# LPC11xxLV_LPC111x_LV register map
File version: 1
CPU: CM0 r0p0, little endian, no MPU, no FPU, 2 interrupt priority bits
Registers are 32-bit, read-write, reset 0x0 unless marked. A register's access mark holds for its fields unless they carry their own. Offsets are from the block's base; [hi:lo] are bit positions; 'fields as' and 'values as' point back to an identical list.

## IOCON — I/O configuration (IOCONFIG)
Base 0x40044000
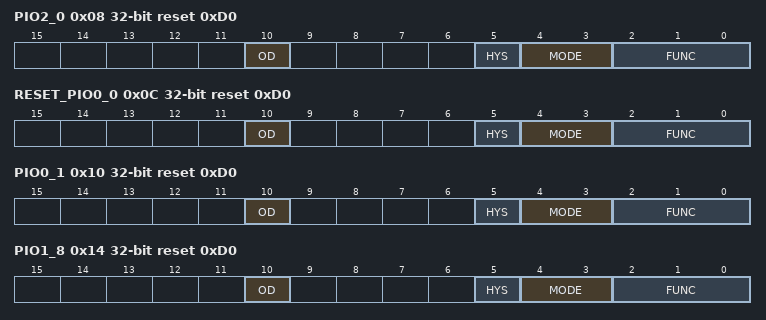
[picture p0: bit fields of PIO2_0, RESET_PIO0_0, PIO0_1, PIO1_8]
0x08 PIO2_0 reset 0xD0 — I/O configuration for pin PIO2_0/DTR/SSEL1
  [10] OD — Selects pseudo open-drain mode.
    0=STANDARD_GPIO_OUTPUT; 1=OPEN_DRAIN_OUTPUT
  [5] HYS — Hysteresis.
    0=DISABLE_; 1=ENABLE_
  [4:3] MODE — Selects function mode (on-chip pull-up/pull-down resistor control).
    0=INACTIVE_NO_PULL_DO (Inactive (no pull-down/pull-up resistor enabled).); 1=PULL_DOWN_RESISTOR_E (Pull-down resistor enabled.); 2=PULL_UP_RESISTOR_ENA (Pull-up resistor enabled.); 3=REPEATER_MODE_
  [2:0] FUNC — Selects pin function. All other values are reserved.
    0=SELECTS_FUNCTION_PIO (Selects function PIO2_0.); 1=SELECT_FUNCTION_DTR_
0x0C RESET_PIO0_0 reset 0xD0 — I/O configuration for pin RESET/PIO0_0
  [10] OD — Selects pseudo open-drain mode.
    0=STANDARD_GPIO_OUTPUT; 1=OPEN_DRAIN_OUTPUT
  [5] HYS — Hysteresis.
    0=DISABLE_; 1=ENABLE_
  [4:3] MODE — Selects function mode (on-chip pull-up/pull-down resistor control).
    values as PIO2_0.MODE
  [2:0] FUNC — Selects pin function. All other values are reserved.
    0=SELECTS_FUNCTION_RES (Selects function RESET.); 1=SELECTS_FUNCTION_PIO0_0
0x10 PIO0_1 reset 0xD0 — I/O configuration for pin PIO0_1/CLKOUT/CT32B0_MAT2
  [10] OD — Selects pseudo open-drain mode.
    0=STANDARD_GPIO_OUTPUT; 1=OPEN_DRAIN_OUTPUT
  [5] HYS — Hysteresis.
    0=DISABLE_; 1=ENABLE_
  [4:3] MODE — Selects function mode (on-chip pull-up/pull-down resistor control).
    values as PIO2_0.MODE
  [2:0] FUNC — Selects pin function. All other values are reserved.
    0=SELECTS_FUNCTION_PIO0_1; 1=SELECTS_FUNCTION_CLKOUT; 2=SELECTS_FUNCTION_CT32B0_MAT2
0x14 PIO1_8 reset 0xD0 — I/O configuration for pin PIO1_8/CT16B1_CAP0
  [10] OD — Selects pseudo open-drain mode.
    0=STANDARD_GPIO_OUTPUT; 1=OPEN_DRAIN_OUTPUT
  [5] HYS — Hysteresis.
    0=DISABLE_; 1=ENABLE_
  [4:3] MODE — Selects function mode (on-chip pull-up/pull-down resistor control).
    values as PIO2_0.MODE
  [2:0] FUNC — Selects pin function. All other values are reserved.
    0=SELECTS_FUNCTION_PIO1_8; 1=SELECTS_FUNCTION_CT16B1_CAP0
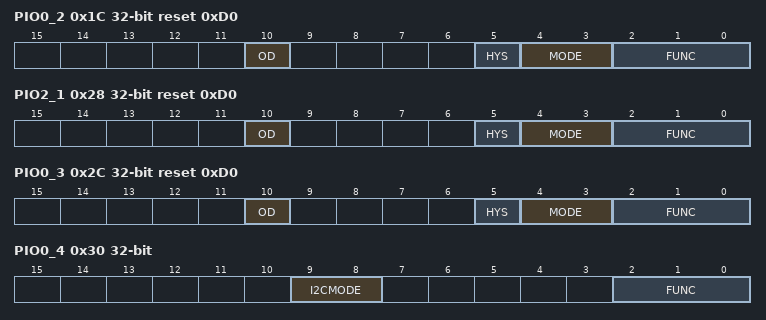
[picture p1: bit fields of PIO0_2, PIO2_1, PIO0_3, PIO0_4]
0x1C PIO0_2 reset 0xD0 — I/O configuration for pin PIO0_2/SSEL0/CT16B0_CAP0
  [10] OD — Selects pseudo open-drain mode.
    0=STANDARD_GPIO_OUTPUT; 1=OPEN_DRAIN_OUTPUT
  [5] HYS — Hysteresis.
    0=DISABLE_; 1=ENABLE_
  [4:3] MODE — Selects function mode (on-chip pull-up/pull-down resistor control).
    values as PIO2_0.MODE
  [2:0] FUNC — Selects pin function. All other values are reserved.
    0=SELECTS_FUNCTION_PIO0_2; 1=SELECTS_FUNCTION_SSE (Selects function SSEL0.); 2=SELECTS_FUNCTION_CT16B0_CAP0
0x28 PIO2_1 reset 0xD0 — I/O configuration for pin PIO2_1/DSR
  [10] OD — Selects pseudo open-drain mode.
    0=STANDARD_GPIO_OUTPUT; 1=OPEN_DRAIN_OUTPUT
  [5] HYS — Hysteresis.
    0=DISABLE_; 1=ENABLE_
  [4:3] MODE — Selects function mode (on-chip pull-up/pull-down resistor control).
    values as PIO2_0.MODE
  [2:0] FUNC — Selects pin function. All other values are reserved.
    0=SELECTS_FUNCTION_PIO2_1; 1=SELECT_FUNCTION_DSR_
0x2C PIO0_3 reset 0xD0 — I/O configuration for pin PIO0_3
  [10] OD — Selects pseudo open-drain mode.
    0=STANDARD_GPIO_OUTPUT; 1=OPEN_DRAIN_OUTPUT
  [5] HYS — Hysteresis.
    0=DISABLE_; 1=ENABLE_
  [4:3] MODE — Selects function mode (on-chip pull-up/pull-down resistor control).
    values as PIO2_0.MODE
  [2:0] FUNC — Selects pin function. All other values are reserved.
    0=SELECTS_FUNCTION_PIO0_3
0x30 PIO0_4 — I/O configuration for pin PIO0_4/SCL
  [9:8] I2CMODE — Selects I2C mode. Select Standard mode (I2CMODE = 00, default) or Standard I/O functionality (I2CMODE = 01) if the pin function is GPIO (FUNC = 000).
    0=STANDARD_MODE_FAST (Standard mode/ Fast-mode I2C.); 1=STANDARD_IO_FUNCTION (Standard I/O functionality); 2=FAST_MODE_PLUS_I2C
  [2:0] FUNC — Selects pin function. All other values are reserved.
    0=SELECTS_FUNCTION_PIO0_4 (Selects function PIO0_4 (open-drain pin).); 1=SELECTS_FUNCTION_SCL (Selects I2C function SCL (open-drain pin).)
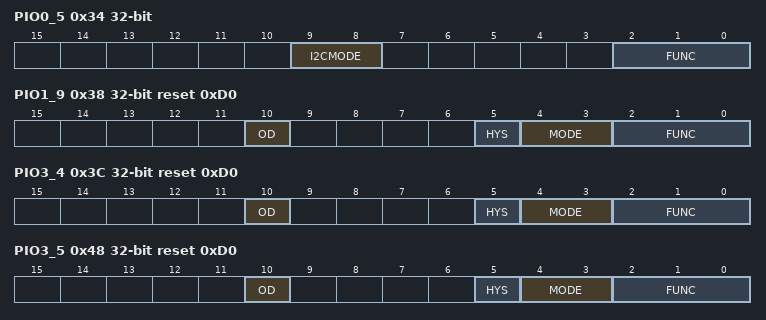
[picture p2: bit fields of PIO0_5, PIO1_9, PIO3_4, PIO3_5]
0x34 PIO0_5 — I/O configuration for pin PIO0_5/SDA
  [9:8] I2CMODE — Selects I2C mode. Select Standard mode (I2CMODE = 00, default) or Standard I/O functionality (I2CMODE = 01) if the pin function is GPIO (FUNC = 000).
    values as PIO0_4.I2CMODE
  [2:0] FUNC — Selects pin function. All other values are reserved.
    0=SELECTS_FUNCTION_PIO0_5 (Selects function PIO0_5 (open-drain pin).); 1=SELECTS_FUNCTION_SDA (Selects I2C function SDA (open-drain pin).)
0x38 PIO1_9 reset 0xD0 — I/O configuration for pin PIO1_9/CT16B1_MAT0/ MOSI1
  [10] OD — Selects pseudo open-drain mode.
    0=STANDARD_GPIO_OUTPUT; 1=OPEN_DRAIN_OUTPUT
  [5] HYS — Hysteresis.
    0=DISABLE_; 1=ENABLE_
  [4:3] MODE — Selects function mode (on-chip pull-up/pull-down resistor control).
    values as PIO2_0.MODE
  [2:0] FUNC — Selects pin function. All other values are reserved.
    0=SELECTS_FUNCTION_PIO1_9; 1=SELECTS_FUNCTION_CT16B1_MAT0
0x3C PIO3_4 reset 0xD0 — I/O configuration for pin PIO3_4/CT16B0_CAP1/RXD
  [10] OD — Selects pseudo open-drain mode.
    0=STANDARD_GPIO_OUTPUT; 1=OPEN_DRAIN_OUTPUT
  [5] HYS — Hysteresis.
    0=DISABLE_; 1=ENABLE_
  [4:3] MODE — Selects function mode (on-chip pull-up/pull-down resistor control).
    values as PIO2_0.MODE
  [2:0] FUNC — Selects pin function. All other values are reserved.
    0=SELECTS_FUNCTION_PIO3_4; 1=SELECTS_FUNCTION_CT16B0_CAP1; 2=SELECTS_FUNCTION_RXD (Selects function RXD. Also select the RXD location in the RXD_LOC register.)
0x48 PIO3_5 reset 0xD0 — I/O configuration for pin PIO3_5/CT16B1_CAP1/TXD
  [10] OD — Selects pseudo open-drain mode.
    0=STANDARD_GPIO_OUTPUT; 1=OPEN_DRAIN_OUTPUT
  [5] HYS — Hysteresis.
    0=DISABLE_; 1=ENABLE_
  [4:3] MODE — Selects function mode (on-chip pull-up/pull-down resistor control).
    values as PIO2_0.MODE
  [2:0] FUNC — Selects pin function. All other values are reserved.
    0=SELECTS_FUNCTION_PIO3_5; 1=SELECTS_FUNCTION_CT16B1_CAP1; 2=SELECTS_FUNCTION_TXD
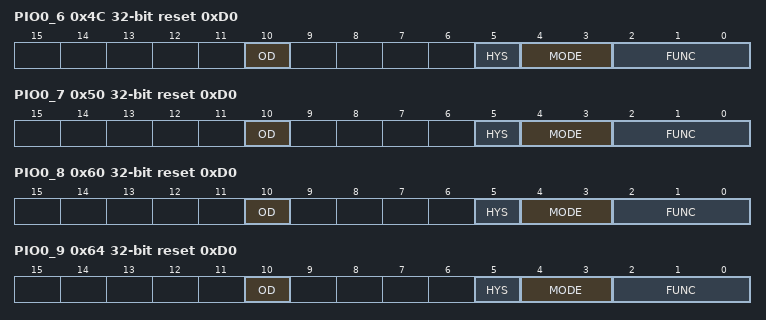
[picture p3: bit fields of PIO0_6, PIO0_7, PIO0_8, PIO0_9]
0x4C PIO0_6 reset 0xD0 — I/O configuration for pin PIO0_6/SCK0
  [10] OD — Selects pseudo open-drain mode.
    0=STANDARD_GPIO_OUTPUT; 1=OPEN_DRAIN_OUTPUT
  [5] HYS — Hysteresis.
    0=DISABLE_; 1=ENABLE_
  [4:3] MODE — Selects function mode (on-chip pull-up/pull-down resistor control).
    values as PIO2_0.MODE
  [2:0] FUNC — Selects pin function. All other values are reserved.
    0=SELECTS_FUNCTION_PIO0_6; 2=SELECTS_FUNCTION_SCK0 (Selects function SCK0 (only if pin PIO0_6/SCK0 selected in Table 147).)
0x50 PIO0_7 reset 0xD0 — I/O configuration for pin PIO0_7/CTS
  [10] OD — Selects pseudo open-drain mode.
    0=STANDARD_GPIO_OUTPUT; 1=OPEN_DRAIN_OUTPUT
  [5] HYS — Hysteresis.
    0=DISABLE_; 1=ENABLE_
  [4:3] MODE — Selects function mode (on-chip pull-up/pull-down resistor control).
    values as PIO2_0.MODE
  [2:0] FUNC — Selects pin function. All other values are reserved.
    0=SELECTS_FUNCTION_PIO (Selects function PIO0_7.); 1=SELECT_FUNCTION_CTS_
0x60 PIO0_8 reset 0xD0 — I/O configuration for pin PIO0_8/MISO0/CT16B0_MAT0
  [10] OD — Selects pseudo open-drain mode.
    0=STANDARD_GPIO_OUTPUT; 1=OPEN_DRAIN_OUTPUT
  [5] HYS — Hysteresis.
    0=DISABLE_; 1=ENABLE_
  [4:3] MODE — Selects function mode (on-chip pull-up/pull-down resistor control).
    values as PIO2_0.MODE
  [2:0] FUNC — Selects pin function. All other values are reserved.
    0=SELECTS_FUNCTION_PIO0_8; 1=SELECTS_FUNCTION_MISO0; 2=SELECTS_FUNCTION_CT16B0_MAT0
0x64 PIO0_9 reset 0xD0 — I/O configuration for pin PIO0_9/MOSI0/CT16B0_MAT1
  [10] OD — Selects pseudo open-drain mode.
    0=STANDARD_GPIO_OUTPUT; 1=OPEN_DRAIN_OUTPUT
  [5] HYS — Hysteresis.
    0=DISABLE_; 1=ENABLE_
  [4:3] MODE — Selects function mode (on-chip pull-up/pull-down resistor control).
    values as PIO2_0.MODE
  [2:0] FUNC — Selects pin function. All other values are reserved.
    0=SELECTS_FUNCTION_PIO0_9; 1=SELECTS_FUNCTION_MOSI0; 2=SELECTS_FUNCTION_CT16B0_MAT1
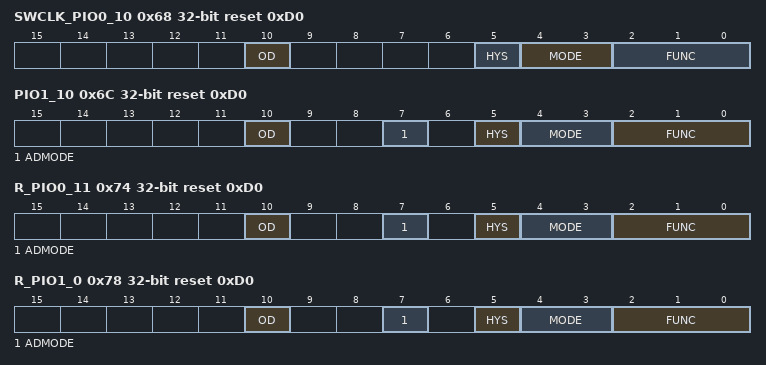
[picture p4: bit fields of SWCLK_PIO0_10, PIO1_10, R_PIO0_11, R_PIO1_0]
0x68 SWCLK_PIO0_10 reset 0xD0 — I/O configuration for pin SWCLK/PIO0_10/ SCK0/CT16B0_MAT2
  [10] OD — Selects pseudo open-drain mode.
    0=STANDARD_GPIO_OUTPUT; 1=OPEN_DRAIN_OUTPUT
  [5] HYS — Hysteresis.
    0=DISABLE_; 1=ENABLE_
  [4:3] MODE — Selects function mode (on-chip pull-up/pull-down resistor control).
    values as PIO2_0.MODE
  [2:0] FUNC — Selects pin function. All other values are reserved.
    0=SELECTS_FUNCTION_SWCLK; 1=SELECTS_FUNCTION_PIO0_10; 2=SELECTS_FUNCTION_SCK0 (Selects function SCK0 (only if pin SWCLK/PIO0_10/SCK0/CT16B0_MAT2 selected in Table 147).); 3=SELECTS_FUNCTION_CT16B0_MAT2
0x6C PIO1_10 reset 0xD0 — I/O configuration for pin PIO1_10/AD6/CT16B1_MAT1/ MISO1
  [10] OD — Selects pseudo open-drain mode.
    0=STANDARD_GPIO_OUTPUT; 1=OPEN_DRAIN_OUTPUT
  [7] ADMODE — Selects Analog/Digital mode
    0=ANALOG_INPUT_MODE; 1=DIGITAL_FUNCTIONAL_M (Digital functional mode)
  [5] HYS — Hysteresis.
    0=DISABLE_; 1=ENABLE_
  [4:3] MODE — Selects function mode (on-chip pull-up/pull-down resistor control).
    values as PIO2_0.MODE
  [2:0] FUNC — Selects pin function. All other values are reserved.
    0=SELECTS_FUNCTION_PIO1_10; 1=SELECTS_FUNCTION_AD6; 2=SELECTS_FUNCTION_CT16B1_MAT1
0x74 R_PIO0_11 reset 0xD0 — I/O configuration for pin R/PIO0_11/AD0/CT32B0_MAT3
  [10] OD — Selects pseudo open-drain mode.
    0=STANDARD_GPIO_OUTPUT; 1=OPEN_DRAIN_OUTPUT
  [7] ADMODE — Selects Analog/Digital mode
    values as PIO1_10.ADMODE
  [5] HYS — Hysteresis.
    0=DISABLE_; 1=ENABLE_
  [4:3] MODE — Selects function mode (on-chip pull-up/pull-down resistor control).
    values as PIO2_0.MODE
  [2:0] FUNC — Selects pin function. All other values are reserved.
    0=SELECTS_FUNCTION_R_ (Selects function R. This function is reserved. Select one of the alternate functions below.); 1=SELECTS_FUNCTION_PIO0_11; 2=SELECTS_FUNCTION_AD0; 3=SELECTS_FUNCTION_CT32B0_MAT3
0x78 R_PIO1_0 reset 0xD0 — I/O configuration for pin R/PIO1_0/AD1/CT32B1_CAP0
  [10] OD — Selects pseudo open-drain mode.
    0=STANDARD_GPIO_OUTPUT; 1=OPEN_DRAIN_OUTPUT
  [7] ADMODE — Selects Analog/Digital mode
    values as PIO1_10.ADMODE
  [5] HYS — Hysteresis.
    0=DISABLE_; 1=ENABLE_
  [4:3] MODE — Selects function mode (on-chip pull-up/pull-down resistor control).
    values as PIO2_0.MODE
  [2:0] FUNC — Selects pin function. All other values are reserved.
    0=SELECTS_FUNCTION_R_ (Selects function R. This function is reserved. Select one of the alternate functions below.); 1=SELECTS_FUNCTION_PIO1_0; 2=SELECTS_FUNCTION_AD1; 3=SELECTS_FUNCTION_CT32B1_CAP0
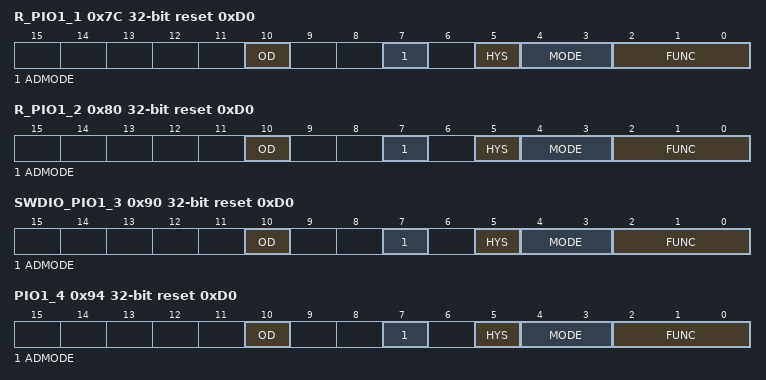
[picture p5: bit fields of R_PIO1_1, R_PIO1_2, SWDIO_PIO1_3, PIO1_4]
0x7C R_PIO1_1 reset 0xD0 — I/O configuration for pin R/PIO1_1/AD2/CT32B1_MAT0
  [10] OD — Selects pseudo open-drain mode.
    0=STANDARD_GPIO_OUTPUT; 1=OPEN_DRAIN_OUTPUT
  [7] ADMODE — Selects Analog/Digital mode
    values as PIO1_10.ADMODE
  [5] HYS — Hysteresis.
    0=DISABLE_; 1=ENABLE_
  [4:3] MODE — Selects function mode (on-chip pull-up/pull-down resistor control).
    values as PIO2_0.MODE
  [2:0] FUNC — Selects pin function. All other values are reserved.
    0=SELECTS_FUNCTION_R_ (Selects function R. This function is reserved. Select one of the alternate functions below.); 1=SELECTS_FUNCTION_PIO (Selects function PIO1_1.); 2=SELECTS_FUNCTION_AD2; 3=SELECTS_FUNCTION_CT3 (Selects function CT32B1_MAT0.)
0x80 R_PIO1_2 reset 0xD0 — I/O configuration for pin R/PIO1_2/AD3/CT32B1_MAT1
  [10] OD — Selects pseudo open-drain mode.
    0=STANDARD_GPIO_OUTPUT; 1=OPEN_DRAIN_OUTPUT
  [7] ADMODE — Selects Analog/Digital mode
    values as PIO1_10.ADMODE
  [5] HYS — Hysteresis.
    0=DISABLE_; 1=ENABLE_
  [4:3] MODE — Selects function mode (on-chip pull-up/pull-down resistor control).
    values as PIO2_0.MODE
  [2:0] FUNC — Selects pin function. All other values are reserved.
    0=SELECTS_FUNCTION_R_ (Selects function R. This function is reserved. Select one of the alternate functions below.); 1=SELECTS_FUNCTION_PIO1_2; 2=SELECTS_FUNCTION_AD3; 3=SELECTS_FUNCTION_CT32B1_MAT1
0x90 SWDIO_PIO1_3 reset 0xD0 — I/O configuration for pin SWDIO/PIO1_3/AD4/CT32B1_MAT2
  [10] OD — Selects pseudo open-drain mode.
    0=STANDARD_GPIO_OUTPUT; 1=OPEN_DRAIN_OUTPUT
  [7] ADMODE — Selects Analog/Digital mode
    values as PIO1_10.ADMODE
  [5] HYS — Hysteresis.
    0=DISABLE_; 1=ENABLE_
  [4:3] MODE — Selects function mode (on-chip pull-up/pull-down resistor control).
    values as PIO2_0.MODE
  [2:0] FUNC — Selects pin function. All other values are reserved.
    0=SELECTS_FUNCTION_SWDIO; 1=SELECTS_FUNCTION_PIO1_3; 2=SELECTS_FUNCTION_AD4; 3=SELECTS_FUNCTION_CT3 (Selects function CT32B1_MAT2.)
0x94 PIO1_4 reset 0xD0 — I/O configuration for pin PIO1_4/AD5/CT32B1_MAT3
  [10] OD — Selects pseudo open-drain mode.
    0=STANDARD_GPIO_OUTPUT; 1=OPEN_DRAIN_OUTPUT
  [7] ADMODE — Selects Analog/Digital mode
    values as PIO1_10.ADMODE
  [5] HYS — Hysteresis.
    0=DISABLE_; 1=ENABLE_
  [4:3] MODE — Selects function mode (on-chip pull-up/pull-down resistor control).
    values as PIO2_0.MODE
  [2:0] FUNC — Selects pin function. This pin functions as WAKEUP pin if the LPC111x/LPC11Cxx is in Deep power-down mode regardless of the value of FUNC. All other values are reserved.
    0=SELECTS_FUNCTION_PIO1_4; 1=SELECTS_FUNCTION_AD5; 2=SELECTS_FUNCTION_CT32B1_MAT3
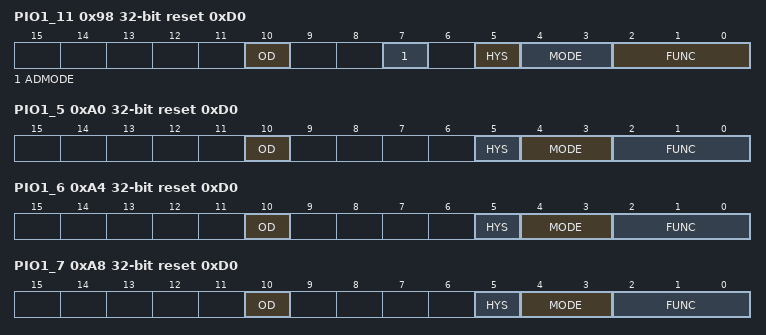
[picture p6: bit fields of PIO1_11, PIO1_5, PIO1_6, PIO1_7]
0x98 PIO1_11 reset 0xD0 — I/O configuration for pin PIO1_11/AD7/CT32B1_CAP1
  [10] OD — Selects pseudo open-drain mode.
    0=STANDARD_GPIO_OUTPUT; 1=OPEN_DRAIN_OUTPUT
  [7] ADMODE — Selects Analog/Digital mode
    values as PIO1_10.ADMODE
  [5] HYS — Hysteresis.
    0=DISABLE_; 1=ENABLE_
  [4:3] MODE — Selects function mode (on-chip pull-up/pull-down resistor control).
    values as PIO2_0.MODE
  [2:0] FUNC — Selects pin function. All other values are reserved.
    0=SELECTS_FUNCTION_PIO1_11; 1=SELECTS_FUNCTION_AD7; 2=SELECTS_FUNCTION_CT32B1_CAP1
0xA0 PIO1_5 reset 0xD0 — I/O configuration for pin PIO1_5/RTS/CT32B0_CAP0
  [10] OD — Selects pseudo open-drain mode.
    0=STANDARD_GPIO_OUTPUT; 1=OPEN_DRAIN_OUTPUT
  [5] HYS — Hysteresis.
    0=DISABLE_; 1=ENABLE_
  [4:3] MODE — Selects function mode (on-chip pull-up/pull-down resistor control).
    values as PIO2_0.MODE
  [2:0] FUNC — Selects pin function. All other values are reserved.
    0=SELECTS_FUNCTION_PIO1_5; 1=SELECTS_FUNCTION_RTS; 2=SELECTS_FUNCTION_CT32B0_CAP0
0xA4 PIO1_6 reset 0xD0 — I/O configuration for pin PIO1_6/RXD/CT32B0_MAT0
  [10] OD — Selects pseudo open-drain mode.
    0=STANDARD_GPIO_OUTPUT; 1=OPEN_DRAIN_OUTPUT
  [5] HYS — Hysteresis.
    0=DISABLE_; 1=ENABLE_
  [4:3] MODE — Selects function mode (on-chip pull-up/pull-down resistor control).
    values as PIO2_0.MODE
  [2:0] FUNC — Selects pin function. All other values are reserved.
    0=SELECTS_FUNCTION_PIO1_6; 1=SELECTS_FUNCTION_RXD (Selects function RXD. Also select the RXD location in the RXD_LOC register.); 2=SELECTS_FUNCTION_CT32B0_MAT0
0xA8 PIO1_7 reset 0xD0 — I/O configuration for pin PIO1_7/TXD/CT32B0_MAT1
  [10] OD — Selects pseudo open-drain mode.
    0=STANDARD_GPIO_OUTPUT; 1=OPEN_DRAIN_OUTPUT
  [5] HYS — Hysteresis.
    0=DISABLE_; 1=ENABLE_
  [4:3] MODE — Selects function mode (on-chip pull-up/pull-down resistor control).
    values as PIO2_0.MODE
  [2:0] FUNC — Selects pin function. All other values are reserved.
    0=SELECTS_FUNCTION_PIO1_7; 1=SELECTS_FUNCTION_TXD; 2=SELECTS_FUNCTION_CT32B0_MAT1
0xB0 SCK0_LOC — SCK0 pin location select register
  [1:0] SCKLOC — Selects pin location for SCK0 function.
    0=SELECTS_SCK0_FUNCTIO (Selects SCK0 function in pin location SWCLK/PIO0_10/SCK0/CT16B0_MAT2 (see Table 129).); 1=SELECTS_SCK0_FUNCTIO (Selects SCK0 function in pin location PIO2_11/SCK0 (see Table 131).); 2=SELECTS_SCK0_FUNCTIO (Selects SCK0 function in pin location PIO0_6/SCK0 (see Table 122).)
0xD4 RXD_LOC — RXD pin location select register
  [1:0] RXDLOC — Selects pin location for the RXD function.
    0=SELECTS_RXD_FUNCTION (Selects RXD function in pin location PIO1_6/RXD/CT32B0_MAT0 (see Table 144).); 1=SELECTS_RXD_FUNCTION (Selects RXD function in pin location PIO2_7/CT32B0_MAT2/RXD (see Table 111).); 2=SELECTS_RXD_FUNCTION (Selects RXD function in pin location PIO3_1/DSR/CT16B0_MAT1/RXD (see Table 137).); 3=SELECTS_RXD_FUNCTION (Selects RXD function in pin location PIO3_4/CT16B0_CAP1/RXD (see Table 118).)
